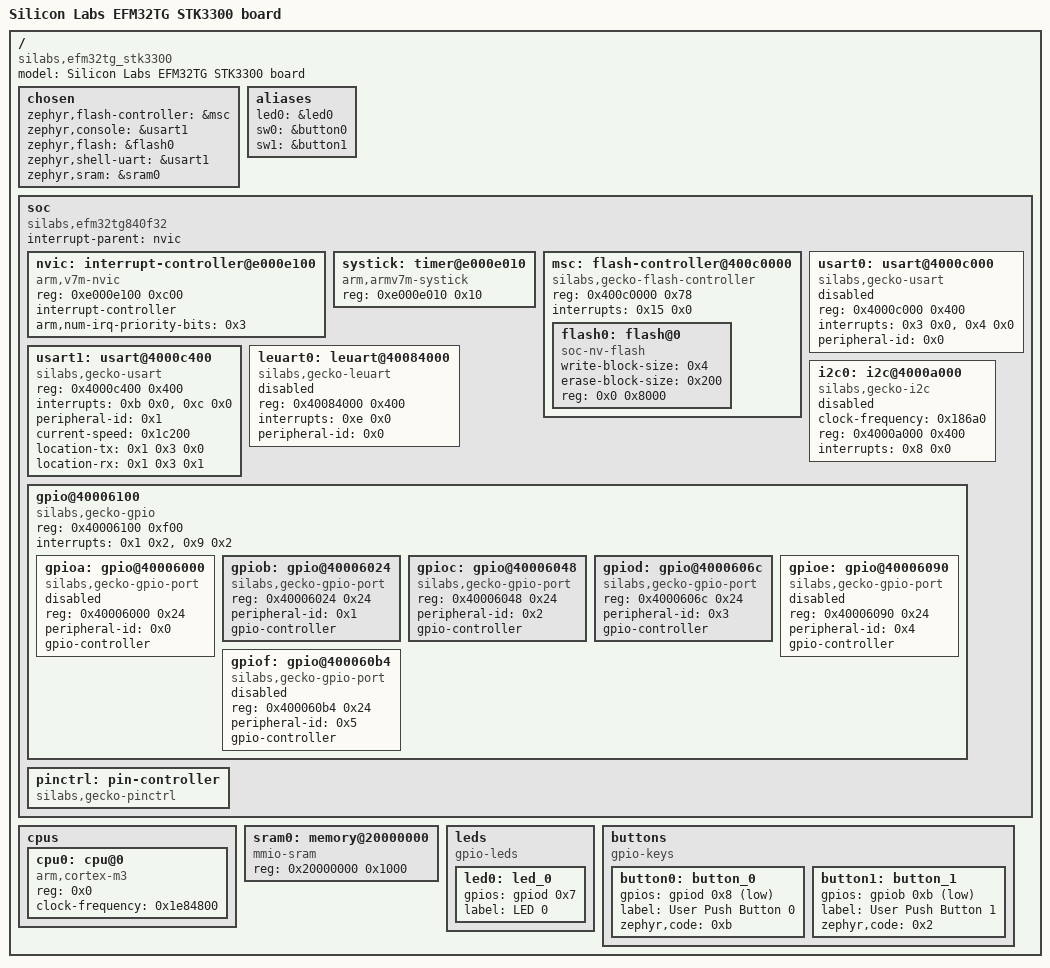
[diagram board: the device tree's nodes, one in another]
/dts-v1/;

/* node '/' defined in zephyr/dts/common/skeleton.dtsi:9 */
/ {
	#address-cells = < 0x1 >;                     /* in zephyr/dts/common/skeleton.dtsi:10 */
	#size-cells = < 0x1 >;                        /* in zephyr/dts/common/skeleton.dtsi:11 */
	model = "Silicon Labs EFM32TG STK3300 board"; /* in zephyr/boards/silabs/starter_kits/efm32tg_stk3300/efm32tg_stk3300.dts:13 */
	compatible = "silabs,efm32tg_stk3300",
	             "silabs,efm32tg";                /* in zephyr/boards/silabs/starter_kits/efm32tg_stk3300/efm32tg_stk3300.dts:14 */

	/* node '/chosen' defined in zephyr/dts/common/skeleton.dtsi:13 */
	chosen {
		zephyr,flash-controller = &msc; /* in zephyr/dts/arm/silabs/efm32tg.dtsi:13 */
		zephyr,console = &usart1;       /* in zephyr/boards/silabs/starter_kits/efm32tg_stk3300/efm32tg_stk3300.dts:17 */
		zephyr,flash = &flash0;         /* in zephyr/boards/silabs/starter_kits/efm32tg_stk3300/efm32tg_stk3300.dts:18 */
		zephyr,shell-uart = &usart1;    /* in zephyr/boards/silabs/starter_kits/efm32tg_stk3300/efm32tg_stk3300.dts:19 */
		zephyr,sram = &sram0;           /* in zephyr/boards/silabs/starter_kits/efm32tg_stk3300/efm32tg_stk3300.dts:20 */
	};

	/* node '/aliases' defined in zephyr/dts/common/skeleton.dtsi:15 */
	aliases {
		led0 = &led0;   /* in zephyr/boards/silabs/starter_kits/efm32tg_stk3300/efm32tg_stk3300.dts:25 */
		sw0 = &button0; /* in zephyr/boards/silabs/starter_kits/efm32tg_stk3300/efm32tg_stk3300.dts:26 */
		sw1 = &button1; /* in zephyr/boards/silabs/starter_kits/efm32tg_stk3300/efm32tg_stk3300.dts:27 */
	};

	/* node '/soc' defined in zephyr/dts/arm/armv7-m.dtsi:6 */
	soc {
		#address-cells = < 0x1 >;            /* in zephyr/dts/arm/armv7-m.dtsi:7 */
		#size-cells = < 0x1 >;               /* in zephyr/dts/arm/armv7-m.dtsi:8 */
		interrupt-parent = < &nvic >;        /* in zephyr/dts/arm/armv7-m.dtsi:10 */
		ranges;                              /* in zephyr/dts/arm/armv7-m.dtsi:11 */
		compatible = "silabs,efm32tg840f32",
		             "silabs,efm32tg",
		             "silabs,efm32",
		             "simple-bus";           /* in zephyr/dts/arm/silabs/efm32tg840f32.dtsi:12 */

		/* node '/soc/interrupt-controller@e000e100' defined in zephyr/dts/arm/armv7-m.dtsi:13 */
		nvic: interrupt-controller@e000e100 {
			#address-cells = < 0x1 >;            /* in zephyr/dts/arm/armv7-m.dtsi:14 */
			compatible = "arm,v7m-nvic";         /* in zephyr/dts/arm/armv7-m.dtsi:15 */
			reg = < 0xe000e100 0xc00 >;          /* in zephyr/dts/arm/armv7-m.dtsi:16 */
			interrupt-controller;                /* in zephyr/dts/arm/armv7-m.dtsi:17 */
			#interrupt-cells = < 0x2 >;          /* in zephyr/dts/arm/armv7-m.dtsi:18 */
			arm,num-irq-priority-bits = < 0x3 >; /* in zephyr/dts/arm/silabs/efm32tg.dtsi:160 */
			phandle = < 0x1 >;                   /* in zephyr/dts/arm/armv7-m.dtsi:10 */
		};

		/* node '/soc/timer@e000e010' defined in zephyr/dts/arm/armv7-m.dtsi:21 */
		systick: timer@e000e010 {
			compatible = "arm,armv7m-systick"; /* in zephyr/dts/arm/armv7-m.dtsi:22 */
			reg = < 0xe000e010 0x10 >;         /* in zephyr/dts/arm/armv7-m.dtsi:23 */
		};

		/* node '/soc/flash-controller@400c0000' defined in zephyr/dts/arm/silabs/efm32tg.dtsi:33 */
		msc: flash-controller@400c0000 {
			compatible = "silabs,gecko-flash-controller"; /* in zephyr/dts/arm/silabs/efm32tg.dtsi:34 */
			reg = < 0x400c0000 0x78 >;                    /* in zephyr/dts/arm/silabs/efm32tg.dtsi:35 */
			interrupts = < 0x15 0x0 >;                    /* in zephyr/dts/arm/silabs/efm32tg.dtsi:36 */
			#address-cells = < 0x1 >;                     /* in zephyr/dts/arm/silabs/efm32tg.dtsi:38 */
			#size-cells = < 0x1 >;                        /* in zephyr/dts/arm/silabs/efm32tg.dtsi:39 */

			/* node '/soc/flash-controller@400c0000/flash@0' defined in zephyr/dts/arm/silabs/efm32tg.dtsi:41 */
			flash0: flash@0 {
				compatible = "soc-nv-flash";  /* in zephyr/dts/arm/silabs/efm32tg.dtsi:42 */
				write-block-size = < 0x4 >;   /* in zephyr/dts/arm/silabs/efm32tg.dtsi:43 */
				erase-block-size = < 0x200 >; /* in zephyr/dts/arm/silabs/efm32tg.dtsi:44 */
				reg = < 0x0 0x8000 >;         /* in zephyr/dts/arm/silabs/efm32tg840f32.dtsi:21 */
			};
		};

		/* node '/soc/usart@4000c000' defined in zephyr/dts/arm/silabs/efm32tg.dtsi:48 */
		usart0: usart@4000c000 {
			compatible = "silabs,gecko-usart"; /* in zephyr/dts/arm/silabs/efm32tg.dtsi:49 */
			reg = < 0x4000c000 0x400 >;        /* in zephyr/dts/arm/silabs/efm32tg.dtsi:50 */
			interrupts = < 0x3 0x0 >,
			             < 0x4 0x0 >;          /* in zephyr/dts/arm/silabs/efm32tg.dtsi:51 */
			interrupt-names = "rx",
			                  "tx";            /* in zephyr/dts/arm/silabs/efm32tg.dtsi:52 */
			peripheral-id = < 0x0 >;           /* in zephyr/dts/arm/silabs/efm32tg.dtsi:53 */
			status = "disabled";               /* in zephyr/dts/arm/silabs/efm32tg.dtsi:54 */
		};

		/* node '/soc/usart@4000c400' defined in zephyr/dts/arm/silabs/efm32tg.dtsi:57 */
		usart1: usart@4000c400 {
			compatible = "silabs,gecko-usart"; /* in zephyr/dts/arm/silabs/efm32tg.dtsi:58 */
			reg = < 0x4000c400 0x400 >;        /* in zephyr/dts/arm/silabs/efm32tg.dtsi:59 */
			interrupts = < 0xb 0x0 >,
			             < 0xc 0x0 >;          /* in zephyr/dts/arm/silabs/efm32tg.dtsi:60 */
			interrupt-names = "rx",
			                  "tx";            /* in zephyr/dts/arm/silabs/efm32tg.dtsi:61 */
			peripheral-id = < 0x1 >;           /* in zephyr/dts/arm/silabs/efm32tg.dtsi:62 */
			current-speed = < 0x1c200 >;       /* in zephyr/boards/silabs/starter_kits/efm32tg_stk3300/efm32tg_stk3300.dts:75 */
			location-tx = < 0x1 0x3 0x0 >;     /* in zephyr/boards/silabs/starter_kits/efm32tg_stk3300/efm32tg_stk3300.dts:76 */
			location-rx = < 0x1 0x3 0x1 >;     /* in zephyr/boards/silabs/starter_kits/efm32tg_stk3300/efm32tg_stk3300.dts:77 */
			status = "okay";                   /* in zephyr/boards/silabs/starter_kits/efm32tg_stk3300/efm32tg_stk3300.dts:78 */
		};

		/* node '/soc/leuart@40084000' defined in zephyr/dts/arm/silabs/efm32tg.dtsi:66 */
		leuart0: leuart@40084000 {
			compatible = "silabs,gecko-leuart"; /* in zephyr/dts/arm/silabs/efm32tg.dtsi:67 */
			reg = < 0x40084000 0x400 >;         /* in zephyr/dts/arm/silabs/efm32tg.dtsi:68 */
			interrupts = < 0xe 0x0 >;           /* in zephyr/dts/arm/silabs/efm32tg.dtsi:69 */
			peripheral-id = < 0x0 >;            /* in zephyr/dts/arm/silabs/efm32tg.dtsi:70 */
			status = "disabled";                /* in zephyr/dts/arm/silabs/efm32tg.dtsi:71 */
		};

		/* node '/soc/i2c@4000a000' defined in zephyr/dts/arm/silabs/efm32tg.dtsi:74 */
		i2c0: i2c@4000a000 {
			compatible = "silabs,gecko-i2c"; /* in zephyr/dts/arm/silabs/efm32tg.dtsi:75 */
			clock-frequency = < 0x186a0 >;   /* in zephyr/dts/arm/silabs/efm32tg.dtsi:76 */
			#address-cells = < 0x1 >;        /* in zephyr/dts/arm/silabs/efm32tg.dtsi:77 */
			#size-cells = < 0x0 >;           /* in zephyr/dts/arm/silabs/efm32tg.dtsi:78 */
			reg = < 0x4000a000 0x400 >;      /* in zephyr/dts/arm/silabs/efm32tg.dtsi:79 */
			interrupts = < 0x8 0x0 >;        /* in zephyr/dts/arm/silabs/efm32tg.dtsi:80 */
			status = "disabled";             /* in zephyr/dts/arm/silabs/efm32tg.dtsi:81 */
		};

		/* node '/soc/gpio@40006100' defined in zephyr/dts/arm/silabs/efm32tg.dtsi:84 */
		gpio@40006100 {
			compatible = "silabs,gecko-gpio"; /* in zephyr/dts/arm/silabs/efm32tg.dtsi:85 */
			reg = < 0x40006100 0xf00 >;       /* in zephyr/dts/arm/silabs/efm32tg.dtsi:86 */
			interrupts = < 0x1 0x2 >,
			             < 0x9 0x2 >;         /* in zephyr/dts/arm/silabs/efm32tg.dtsi:87 */
			interrupt-names = "GPIO_EVEN",
			                  "GPIO_ODD";     /* in zephyr/dts/arm/silabs/efm32tg.dtsi:88 */
			ranges;                           /* in zephyr/dts/arm/silabs/efm32tg.dtsi:90 */
			#address-cells = < 0x1 >;         /* in zephyr/dts/arm/silabs/efm32tg.dtsi:91 */
			#size-cells = < 0x1 >;            /* in zephyr/dts/arm/silabs/efm32tg.dtsi:92 */

			/* node '/soc/gpio@40006100/gpio@40006000' defined in zephyr/dts/arm/silabs/efm32tg.dtsi:94 */
			gpioa: gpio@40006000 {
				compatible = "silabs,gecko-gpio-port"; /* in zephyr/dts/arm/silabs/efm32tg.dtsi:95 */
				reg = < 0x40006000 0x24 >;             /* in zephyr/dts/arm/silabs/efm32tg.dtsi:96 */
				peripheral-id = < 0x0 >;               /* in zephyr/dts/arm/silabs/efm32tg.dtsi:97 */
				gpio-controller;                       /* in zephyr/dts/arm/silabs/efm32tg.dtsi:98 */
				#gpio-cells = < 0x2 >;                 /* in zephyr/dts/arm/silabs/efm32tg.dtsi:99 */
				status = "disabled";                   /* in zephyr/dts/arm/silabs/efm32tg.dtsi:100 */
			};

			/* node '/soc/gpio@40006100/gpio@40006024' defined in zephyr/dts/arm/silabs/efm32tg.dtsi:103 */
			gpiob: gpio@40006024 {
				compatible = "silabs,gecko-gpio-port"; /* in zephyr/dts/arm/silabs/efm32tg.dtsi:104 */
				reg = < 0x40006024 0x24 >;             /* in zephyr/dts/arm/silabs/efm32tg.dtsi:105 */
				peripheral-id = < 0x1 >;               /* in zephyr/dts/arm/silabs/efm32tg.dtsi:106 */
				gpio-controller;                       /* in zephyr/dts/arm/silabs/efm32tg.dtsi:107 */
				#gpio-cells = < 0x2 >;                 /* in zephyr/dts/arm/silabs/efm32tg.dtsi:108 */
				status = "okay";                       /* in zephyr/boards/silabs/starter_kits/efm32tg_stk3300/efm32tg_stk3300.dts:63 */
				phandle = < 0x3 >;                     /* in zephyr/boards/silabs/starter_kits/efm32tg_stk3300/efm32tg_stk3300.dts:51 */
			};

			/* node '/soc/gpio@40006100/gpio@40006048' defined in zephyr/dts/arm/silabs/efm32tg.dtsi:112 */
			gpioc: gpio@40006048 {
				compatible = "silabs,gecko-gpio-port"; /* in zephyr/dts/arm/silabs/efm32tg.dtsi:113 */
				reg = < 0x40006048 0x24 >;             /* in zephyr/dts/arm/silabs/efm32tg.dtsi:114 */
				peripheral-id = < 0x2 >;               /* in zephyr/dts/arm/silabs/efm32tg.dtsi:115 */
				gpio-controller;                       /* in zephyr/dts/arm/silabs/efm32tg.dtsi:116 */
				#gpio-cells = < 0x2 >;                 /* in zephyr/dts/arm/silabs/efm32tg.dtsi:117 */
				status = "okay";                       /* in zephyr/boards/silabs/starter_kits/efm32tg_stk3300/efm32tg_stk3300.dts:67 */
			};

			/* node '/soc/gpio@40006100/gpio@4000606c' defined in zephyr/dts/arm/silabs/efm32tg.dtsi:121 */
			gpiod: gpio@4000606c {
				compatible = "silabs,gecko-gpio-port"; /* in zephyr/dts/arm/silabs/efm32tg.dtsi:122 */
				reg = < 0x4000606c 0x24 >;             /* in zephyr/dts/arm/silabs/efm32tg.dtsi:123 */
				peripheral-id = < 0x3 >;               /* in zephyr/dts/arm/silabs/efm32tg.dtsi:124 */
				gpio-controller;                       /* in zephyr/dts/arm/silabs/efm32tg.dtsi:125 */
				#gpio-cells = < 0x2 >;                 /* in zephyr/dts/arm/silabs/efm32tg.dtsi:126 */
				status = "okay";                       /* in zephyr/boards/silabs/starter_kits/efm32tg_stk3300/efm32tg_stk3300.dts:71 */
				phandle = < 0x2 >;                     /* in zephyr/boards/silabs/starter_kits/efm32tg_stk3300/efm32tg_stk3300.dts:34 */
			};

			/* node '/soc/gpio@40006100/gpio@40006090' defined in zephyr/dts/arm/silabs/efm32tg.dtsi:130 */
			gpioe: gpio@40006090 {
				compatible = "silabs,gecko-gpio-port"; /* in zephyr/dts/arm/silabs/efm32tg.dtsi:131 */
				reg = < 0x40006090 0x24 >;             /* in zephyr/dts/arm/silabs/efm32tg.dtsi:132 */
				peripheral-id = < 0x4 >;               /* in zephyr/dts/arm/silabs/efm32tg.dtsi:133 */
				gpio-controller;                       /* in zephyr/dts/arm/silabs/efm32tg.dtsi:134 */
				#gpio-cells = < 0x2 >;                 /* in zephyr/dts/arm/silabs/efm32tg.dtsi:135 */
				status = "disabled";                   /* in zephyr/dts/arm/silabs/efm32tg.dtsi:136 */
			};

			/* node '/soc/gpio@40006100/gpio@400060b4' defined in zephyr/dts/arm/silabs/efm32tg.dtsi:139 */
			gpiof: gpio@400060b4 {
				compatible = "silabs,gecko-gpio-port"; /* in zephyr/dts/arm/silabs/efm32tg.dtsi:140 */
				reg = < 0x400060b4 0x24 >;             /* in zephyr/dts/arm/silabs/efm32tg.dtsi:141 */
				peripheral-id = < 0x5 >;               /* in zephyr/dts/arm/silabs/efm32tg.dtsi:142 */
				gpio-controller;                       /* in zephyr/dts/arm/silabs/efm32tg.dtsi:143 */
				#gpio-cells = < 0x2 >;                 /* in zephyr/dts/arm/silabs/efm32tg.dtsi:144 */
				status = "disabled";                   /* in zephyr/dts/arm/silabs/efm32tg.dtsi:145 */
			};
		};

		/* node '/soc/pin-controller' defined in zephyr/dts/arm/silabs/efm32tg.dtsi:149 */
		pinctrl: pin-controller {
			compatible = "silabs,gecko-pinctrl"; /* in zephyr/dts/arm/silabs/efm32tg.dtsi:154 */
		};
	};

	/* node '/cpus' defined in zephyr/dts/arm/silabs/efm32tg.dtsi:16 */
	cpus {
		#address-cells = < 0x1 >; /* in zephyr/dts/arm/silabs/efm32tg.dtsi:17 */
		#size-cells = < 0x0 >;    /* in zephyr/dts/arm/silabs/efm32tg.dtsi:18 */

		/* node '/cpus/cpu@0' defined in zephyr/dts/arm/silabs/efm32tg.dtsi:20 */
		cpu0: cpu@0 {
			compatible = "arm,cortex-m3";    /* in zephyr/dts/arm/silabs/efm32tg.dtsi:21 */
			device_type = "cpu";             /* in zephyr/dts/arm/silabs/efm32tg.dtsi:22 */
			reg = < 0x0 >;                   /* in zephyr/dts/arm/silabs/efm32tg.dtsi:24 */
			clock-frequency = < 0x1e84800 >; /* in zephyr/boards/silabs/starter_kits/efm32tg_stk3300/efm32tg_stk3300.dts:59 */
		};
	};

	/* node '/memory@20000000' defined in zephyr/dts/arm/silabs/efm32tg.dtsi:28 */
	sram0: memory@20000000 {
		compatible = "mmio-sram";    /* in zephyr/dts/arm/silabs/efm32tg.dtsi:29 */
		reg = < 0x20000000 0x1000 >; /* in zephyr/dts/arm/silabs/efm32tg840f32.dtsi:17 */
	};

	/* node '/leds' defined in zephyr/boards/silabs/starter_kits/efm32tg_stk3300/efm32tg_stk3300.dts:30 */
	leds {
		compatible = "gpio-leds"; /* in zephyr/boards/silabs/starter_kits/efm32tg_stk3300/efm32tg_stk3300.dts:31 */

		/* node '/leds/led_0' defined in zephyr/boards/silabs/starter_kits/efm32tg_stk3300/efm32tg_stk3300.dts:33 */
		led0: led_0 {
			gpios = < &gpiod 0x7 0x0 >; /* in zephyr/boards/silabs/starter_kits/efm32tg_stk3300/efm32tg_stk3300.dts:34 */
			label = "LED 0";            /* in zephyr/boards/silabs/starter_kits/efm32tg_stk3300/efm32tg_stk3300.dts:35 */
		};
	};

	/* node '/buttons' defined in zephyr/boards/silabs/starter_kits/efm32tg_stk3300/efm32tg_stk3300.dts:39 */
	buttons {
		compatible = "gpio-keys"; /* in zephyr/boards/silabs/starter_kits/efm32tg_stk3300/efm32tg_stk3300.dts:40 */

		/* node '/buttons/button_0' defined in zephyr/boards/silabs/starter_kits/efm32tg_stk3300/efm32tg_stk3300.dts:42 */
		button0: button_0 {
			gpios = < &gpiod 0x8 0x1 >;   /* in zephyr/boards/silabs/starter_kits/efm32tg_stk3300/efm32tg_stk3300.dts:44 */
			label = "User Push Button 0"; /* in zephyr/boards/silabs/starter_kits/efm32tg_stk3300/efm32tg_stk3300.dts:45 */
			zephyr,code = < 0xb >;        /* in zephyr/boards/silabs/starter_kits/efm32tg_stk3300/efm32tg_stk3300.dts:46 */
		};

		/* node '/buttons/button_1' defined in zephyr/boards/silabs/starter_kits/efm32tg_stk3300/efm32tg_stk3300.dts:49 */
		button1: button_1 {
			gpios = < &gpiob 0xb 0x1 >;   /* in zephyr/boards/silabs/starter_kits/efm32tg_stk3300/efm32tg_stk3300.dts:51 */
			label = "User Push Button 1"; /* in zephyr/boards/silabs/starter_kits/efm32tg_stk3300/efm32tg_stk3300.dts:52 */
			zephyr,code = < 0x2 >;        /* in zephyr/boards/silabs/starter_kits/efm32tg_stk3300/efm32tg_stk3300.dts:53 */
		};
	};
};
